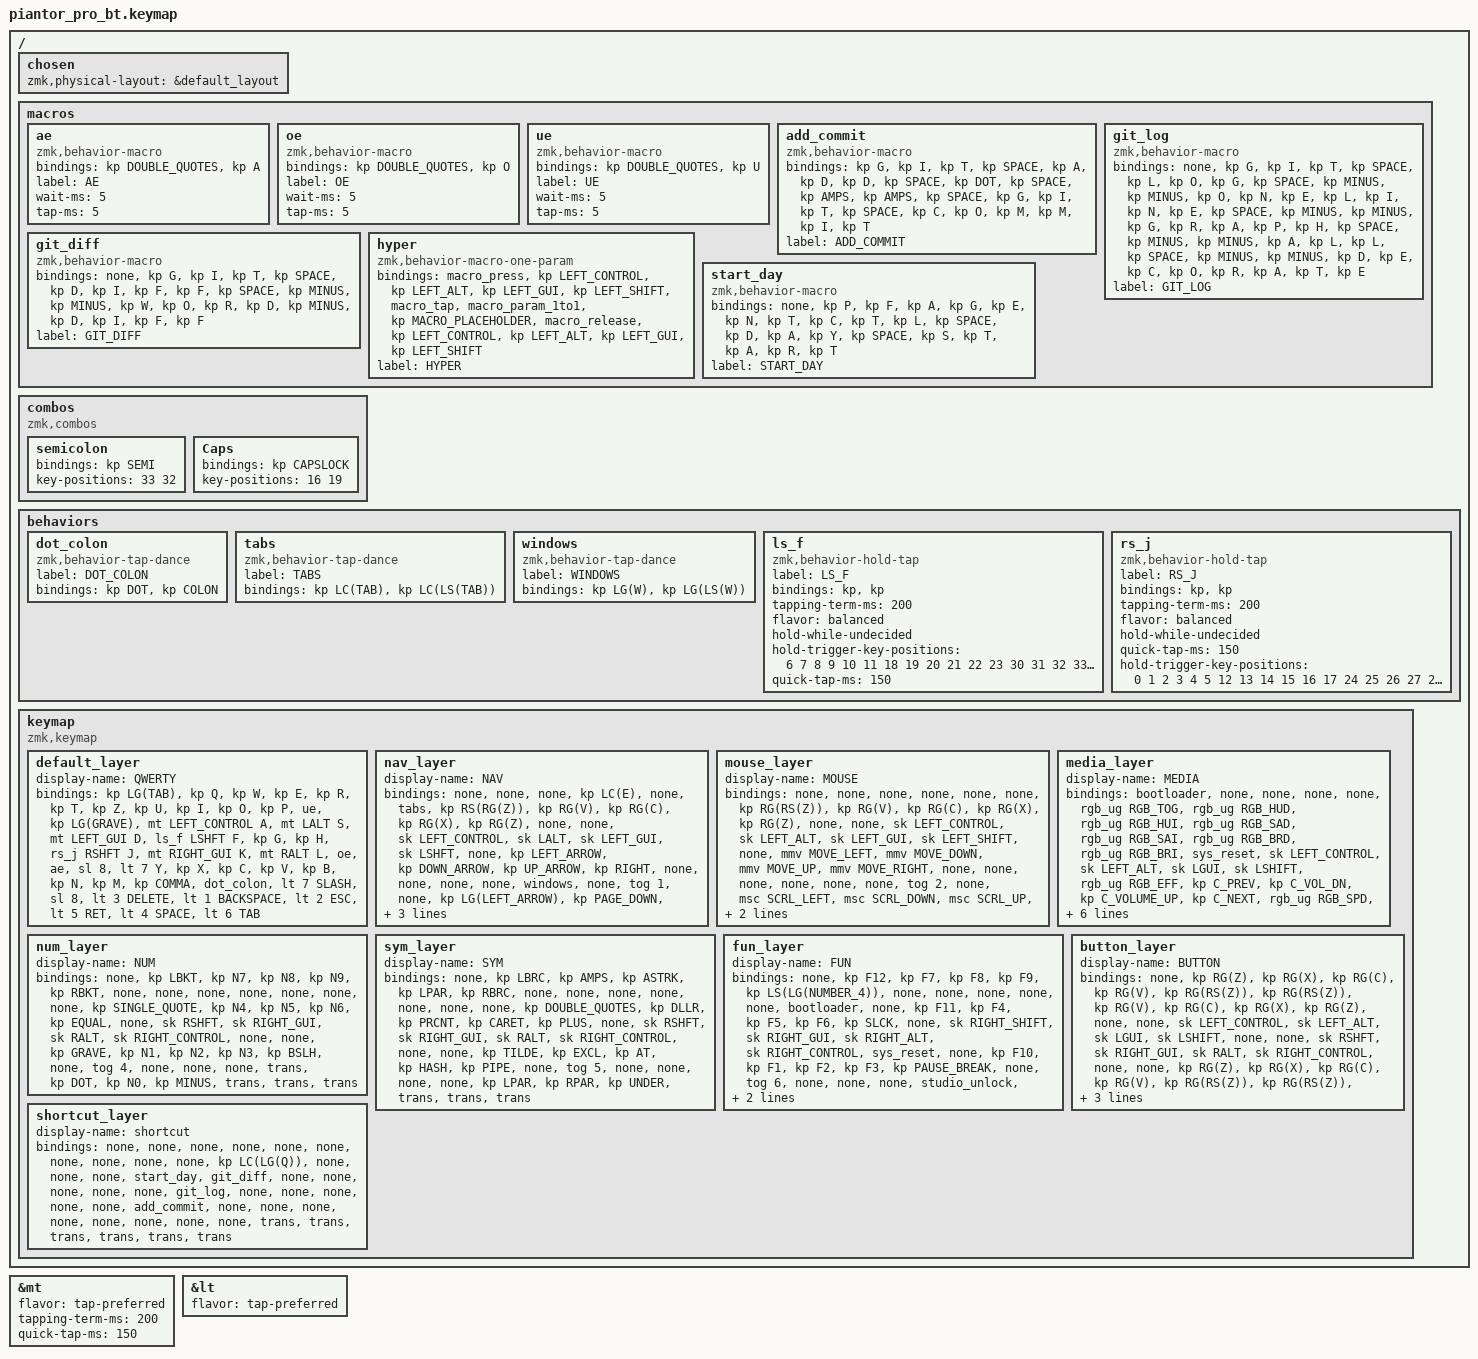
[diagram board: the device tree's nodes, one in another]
/*
 * Copyright (c) 2020 The ZMK Contributors
 *
 * SPDX-License-Identifier: MIT
 */

#define ZMK_POINTING_DEFAULT_MOVE_VAL 2000  // default: 600
#define ZMK_POINTING_DEFAULT_SCRL_VAL 15    // default: 10

#include <behaviors.dtsi>
#include <dt-bindings/zmk/bt.h>
#include <dt-bindings/zmk/keys.h>
#include <dt-bindings/zmk/pointing.h>
#include <dt-bindings/zmk/rgb.h>

&mt {
    flavor = "tap-preferred";
    tapping-term-ms = <200>;
    quick-tap-ms = <150>;
};

&lt { flavor = "tap-preferred"; };

/ {
    chosen { zmk,physical-layout = &default_layout; };

    macros {
        ae: ae {
            compatible = "zmk,behavior-macro";
            #binding-cells = <0>;
            bindings = <&kp DOUBLE_QUOTES &kp A>;
            label = "AE";
            wait-ms = <5>;
            tap-ms = <5>;
        };

        oe: oe {
            compatible = "zmk,behavior-macro";
            #binding-cells = <0>;
            bindings = <&kp DOUBLE_QUOTES &kp O>;
            label = "OE";
            wait-ms = <5>;
            tap-ms = <5>;
        };

        ue: ue {
            compatible = "zmk,behavior-macro";
            #binding-cells = <0>;
            bindings = <&kp DOUBLE_QUOTES &kp U>;
            label = "UE";
            wait-ms = <5>;
            tap-ms = <5>;
        };

        add_commit: add_commit {
            compatible = "zmk,behavior-macro";
            #binding-cells = <0>;
            bindings = <&kp G &kp I &kp T &kp SPACE &kp A &kp D &kp D &kp SPACE &kp DOT &kp SPACE &kp AMPS &kp AMPS &kp SPACE &kp G &kp I &kp T &kp SPACE &kp C &kp O &kp M &kp M &kp I &kp T>;
            label = "ADD_COMMIT";
        };

        git_log: git_log {
            compatible = "zmk,behavior-macro";
            #binding-cells = <0>;
            bindings = <&none &kp G &kp I &kp T &kp SPACE &kp L &kp O &kp G &kp SPACE &kp MINUS &kp MINUS &kp O &kp N &kp E &kp L &kp I &kp N &kp E &kp SPACE &kp MINUS &kp MINUS &kp G &kp R &kp A &kp P &kp H &kp SPACE &kp MINUS &kp MINUS &kp A &kp L &kp L &kp SPACE &kp MINUS &kp MINUS &kp D &kp E &kp C &kp O &kp R &kp A &kp T &kp E>;
            label = "GIT_LOG";
        };

        git_diff: git_diff {
            compatible = "zmk,behavior-macro";
            #binding-cells = <0>;
            bindings = <&none &kp G &kp I &kp T &kp SPACE &kp D &kp I &kp F &kp F &kp SPACE &kp MINUS &kp MINUS &kp W &kp O &kp R &kp D &kp MINUS &kp D &kp I &kp F &kp F>;
            label = "GIT_DIFF";
        };

        hyper: hyper {
            compatible = "zmk,behavior-macro-one-param";
            #binding-cells = <1>;
            bindings =
                <&macro_press>,
                <&kp LEFT_CONTROL &kp LEFT_ALT &kp LEFT_GUI &kp LEFT_SHIFT>,
                <&macro_tap>,
                <&macro_param_1to1 &kp MACRO_PLACEHOLDER>,
                <&macro_release>,
                <&kp LEFT_CONTROL &kp LEFT_ALT &kp LEFT_GUI &kp LEFT_SHIFT>;

            label = "HYPER";
        };

        start_day: start_day {
            compatible = "zmk,behavior-macro";
            #binding-cells = <0>;
            bindings = <&none &kp P &kp F &kp A &kp G &kp E &kp N &kp T &kp C &kp T &kp L &kp SPACE &kp D &kp A &kp Y &kp SPACE &kp S &kp T &kp A &kp R &kp T>;
            label = "START_DAY";
        };
    };

    combos {
        compatible = "zmk,combos";

        semicolon {
            bindings = <&kp SEMI>;
            key-positions = <33 32>;
        };

        Caps {
            bindings = <&kp CAPSLOCK>;
            key-positions = <16 19>;
        };
    };

    behaviors {
        dot_colon: dot_colon {
            compatible = "zmk,behavior-tap-dance";
            label = "DOT_COLON";
            #binding-cells = <0>;
            bindings = <&kp DOT>, <&kp COLON>;
        };

        tabs: tabs {
            compatible = "zmk,behavior-tap-dance";
            label = "TABS";
            #binding-cells = <0>;
            bindings = <&kp LC(TAB)>, <&kp LC(LS(TAB))>;
        };

        windows: windows {
            compatible = "zmk,behavior-tap-dance";
            label = "WINDOWS";
            #binding-cells = <0>;
            bindings = <&kp LG(W)>, <&kp LG(LS(W))>;
        };

        ls_f: ls_f {
            compatible = "zmk,behavior-hold-tap";
            label = "LS_F";
            bindings = <&kp>, <&kp>;

            #binding-cells = <2>;
            tapping-term-ms = <200>;
            flavor = "balanced";
            hold-while-undecided;
            hold-trigger-key-positions = <6 7 8 9 10 11 18 19 20 21 22 23 30 31 32 33 34 35 39 40 41>;
            quick-tap-ms = <150>;
        };

        rs_j: rs_j {
            compatible = "zmk,behavior-hold-tap";
            label = "RS_J";
            bindings = <&kp>, <&kp>;

            #binding-cells = <2>;
            tapping-term-ms = <200>;
            flavor = "balanced";
            hold-while-undecided;
            quick-tap-ms = <150>;
            hold-trigger-key-positions = <0 1 2 3 4 5 12 13 14 15 16 17 24 25 26 27 28 29 36 37 38>;
        };
    };
};

/ {
    keymap {
        compatible = "zmk,keymap";

        default_layer {
            display-name = "QWERTY";

            //---------------------------------------------------------------------------------
            //| LG+TAB | Q | W | E | R | T | Z | U | I | O | P | UE |
            //| LG+` | A/CTRL | S/ALT | D/GUI | F/SHIFT | G | H | J/RSHIFT | K/RGUI | L/RALT | 0/RCTRL | AE |
            //| SL8 | Y/LT7 | X | C | V | B | N | M | '/\" | ./: | /?/! | SL8 |
            //| DEL/LT3 | BSPC/LT1 | ESC/LT2 | RET/LT5 | SPC/LT4 | TAB/LT6 |

            bindings = <
&kp LG(TAB)  &kp Q  &kp W  &kp E  &kp R  &kp T  &kp Z  &kp U  &kp I  &kp O  &kp P  &ue  &kp LG(GRAVE)  &mt LEFT_CONTROL A  &mt LALT S  &mt LEFT_GUI D  &ls_f LSHFT F  &kp G  &kp H  &rs_j RSHFT J  &mt RIGHT_GUI K  &mt RALT L  &oe  &ae  &sl 8  &lt 7 Y  &kp X  &kp C  &kp V  &kp B  &kp N  &kp M  &kp COMMA  &dot_colon  &lt 7 SLASH  &sl 8  &lt 3 DELETE  &lt 1 BACKSPACE  &lt 2 ESC  &lt 5 RET  &lt 4 SPACE  &lt 6 TAB
            >;
        };

        nav_layer {
            display-name = "NAV";

            //-----------------------------------------------------------------------------------
            //|      |     |     | LC+E |     | TABS | REDO | PASTE | COPY | CUT | UNDO |      |
            //|      | CTRL | ALT | GUI | SHIFT |     | LEFT | DOWN | UP | RIGHT |     |      |
            //|      |     |     |     | WINDOWS | TOG MOUSE |     | LG+LEFT | PGDN | RG+PGUP | LG+RIGHT | LG+SPACE |
            //| TRANS | TRANS | TRANS | ENTER | SPACE | TAB |

            bindings = <
&none  &none  &none  &kp LC(E)  &none  &tabs  &kp RS(RG(Z))  &kp RG(V)  &kp RG(C)  &kp RG(X)  &kp RG(Z)  &none  &none  &sk LEFT_CONTROL  &sk LALT  &sk LEFT_GUI  &sk LSHFT  &none  &kp LEFT_ARROW  &kp DOWN_ARROW  &kp UP_ARROW  &kp RIGHT  &none  &none  &none  &none  &windows  &none  &tog 1  &none  &kp LG(LEFT_ARROW)  &kp PAGE_DOWN  &kp PAGE_UP  &kp LG(RIGHT)  &kp LG(SPACE)  &none  &trans  &trans  &trans  &kp ENTER  &kp SPACE  &kp TAB
            >;
        };

        mouse_layer {
            display-name = "MOUSE";

            //-----------------------------------------------------------------------------------
            //|      |     |     |     |     |     | REDO | PASTE | COPY | CUT | UNDO |      |
            //|      | CTRL | ALT | GUI | SHIFT |     | MOVE LEFT | MOVE DOWN | MOVE UP | MOVE RIGHT |     |      |
            //|      |     |     |     |     |     | TOG MOUSE |     | SCROLL LEFT | SCROLL DOWN | SCROLL UP | SCROLL RIGHT |
            //| TRANS | TRANS | TRANS | RCLICK | LCLICK | MCLICK |

            bindings = <
&none  &none  &none  &none  &none  &none  &kp RG(RS(Z))  &kp RG(V)  &kp RG(C)  &kp RG(X)  &kp RG(Z)  &none  &none  &sk LEFT_CONTROL  &sk LEFT_ALT  &sk LEFT_GUI  &sk LEFT_SHIFT  &none  &mmv MOVE_LEFT  &mmv MOVE_DOWN  &mmv MOVE_UP  &mmv MOVE_RIGHT  &none  &none  &none  &none  &none  &none  &tog 2  &none  &msc SCRL_LEFT  &msc SCRL_DOWN  &msc SCRL_UP  &msc SCRL_RIGHT  &none  &none  &trans  &trans  &trans  &mkp RCLK  &mkp LCLK  &mkp MCLK
            >;
        };

        media_layer {
            display-name = "MEDIA";

            //-----------------------------------------------------------------------------
            //| BOOT |     |     |     |     | RGB TOG | HUD | HUI | SAD | SAI | BRD | BRI |
            //| RESET | CTRL | ALT | GUI | SHIFT | EFFECT | PREV | VOL- | VOL+ | NEXT | SPD | SPI |
            //| UNLOCK | RESET | BOOT | UNLOCK | TOG NUM |     | BT CLR | BT1 | BT2 | BT3 | BT4 | BT5 |
            //| TRANS | TRANS | TRANS | STOP | PLAY/PAUSE | MUTE |

            bindings = <
&bootloader  &none  &none  &none  &none  &rgb_ug RGB_TOG  &rgb_ug RGB_HUD  &rgb_ug RGB_HUI  &rgb_ug RGB_SAD  &rgb_ug RGB_SAI  &rgb_ug RGB_BRD  &rgb_ug RGB_BRI  &sys_reset  &sk LEFT_CONTROL  &sk LEFT_ALT  &sk LGUI  &sk LSHIFT  &rgb_ug RGB_EFF  &kp C_PREV  &kp C_VOL_DN  &kp C_VOLUME_UP  &kp C_NEXT  &rgb_ug RGB_SPD  &rgb_ug RGB_SPI  &studio_unlock  &sys_reset  &bootloader  &studio_unlock  &tog 3  &bt BT_CLR  &bt BT_SEL 0  &bt BT_SEL 1  &bt BT_SEL 2  &bt BT_SEL 3  &bt BT_SEL 4  &none  &trans  &trans  &trans  &kp C_STOP  &kp C_PLAY_PAUSE  &kp C_MUTE
            >;
        };

        num_layer {
            display-name = "NUM";

            //----------------------------------------------------------------------------
            //|   | [ | 7 | 8 | 9 | ] |     |     |     |     |     | TRANS |
            //|   | ` | 4 | 5 | 6 | = |     | RSHIFT | RGUI | RALT | RCTRL | TRANS |
            //|   |   | 1 | 2 | 3 | \ |     | TOG SYM |     |     |     | TRANS |
            //| . | 0 | - | TRANS | TRANS | TRANS |

            bindings = <
&none  &kp LBKT  &kp N7  &kp N8  &kp N9  &kp RBKT  &none  &none  &none  &none  &none  &none  &none  &kp SINGLE_QUOTE  &kp N4  &kp N5  &kp N6  &kp EQUAL  &none  &sk RSHFT  &sk RIGHT_GUI  &sk RALT  &sk RIGHT_CONTROL  &none  &none  &kp GRAVE  &kp N1  &kp N2  &kp N3  &kp BSLH  &none  &tog 4  &none  &none  &none  &trans  &kp DOT  &kp N0  &kp MINUS  &trans  &trans  &trans
            >;
        };

        sym_layer {
            display-name = "SYM";

            //-----------------------------------------------------------------------------
            //| TRANS | { | & | * | ( | } |     |     |     |     |     | TRANS |
            //| TRANS | ~ | $ | % | ^ | + |     | RSHIFT | RGUI | RALT | RCTRL | TRANS |
            //| TRANS | NONE | ! | @ | # | | |     | TOG FUN |     |     |     | TRANS |
            //| ( | ) | _ | TRANS | TRANS | TRANS |

            bindings = <
&none  &kp LBRC  &kp AMPS  &kp ASTRK  &kp LPAR  &kp RBRC  &none  &none  &none  &none  &none  &none  &none  &kp DOUBLE_QUOTES  &kp DLLR  &kp PRCNT  &kp CARET  &kp PLUS  &none  &sk RSHFT  &sk RIGHT_GUI  &sk RALT  &sk RIGHT_CONTROL  &none  &none  &kp TILDE  &kp EXCL  &kp AT  &kp HASH  &kp PIPE  &none  &tog 5  &none  &none  &none  &none  &kp LPAR  &kp RPAR  &kp UNDER  &trans  &trans  &trans
            >;
        };

        fun_layer {
            display-name = "FUN";

            //------------------------------------------------------------------------------
            //| TRANS | F12 | F7 | F8 | F9 | SCREENSHOT |     |     |     |     |     | TRANS |
            //| TRANS | F11 | F4 | F5 | F6 | SCROLL LOCK |     | RSHIFT | RGUI | RALT | RCTRL | TRANS |
            //| TRANS | F10 | F1 | F2 | F3 | PAUSE |     | TOG ADJUST |     |     |     | TRANS |
            //| DEL | BSPC | ESC | TRANS | TRANS | TRANS |

            bindings = <
&none  &kp F12  &kp F7  &kp F8  &kp F9  &kp LS(LG(NUMBER_4))  &none  &none  &none  &none  &none  &bootloader  &none  &kp F11  &kp F4  &kp F5  &kp F6  &kp SLCK  &none  &sk RIGHT_SHIFT  &sk RIGHT_GUI  &sk RIGHT_ALT  &sk RIGHT_CONTROL  &sys_reset  &none  &kp F10  &kp F1  &kp F2  &kp F3  &kp PAUSE_BREAK  &none  &tog 6  &none  &none  &none  &studio_unlock  &kp DEL  &kp BACKSPACE  &kp ESC  &trans  &trans  &trans
            >;
        };

        button_layer {
            display-name = "BUTTON";

            //-------------------------------------------------------------------------
            //|      | REDO | CUT | COPY | PASTE | UNDO | UNDO | PASTE | COPY | CUT | REDO |      |
            //|      | CTRL | ALT | GUI | SHIFT |     |     | RSHIFT | RGUI | RALT | RCTRL |      |
            //|      | REDO | CUT | COPY | PASTE | UNDO | UNDO | PASTE | COPY | CUT | REDO |      |
            //| MCLICK | LCLICK | RCLICK | RCLICK | LCLICK | MCLICK |

            bindings = <
&none  &kp RG(Z)  &kp RG(X)  &kp RG(C)  &kp RG(V)  &kp RG(RS(Z))  &kp RG(RS(Z))  &kp RG(V)  &kp RG(C)  &kp RG(X)  &kp RG(Z)  &none  &none  &sk LEFT_CONTROL  &sk LEFT_ALT  &sk LGUI  &sk LSHIFT  &none  &none  &sk RSHFT  &sk RIGHT_GUI  &sk RALT  &sk RIGHT_CONTROL  &none  &none  &kp RG(Z)  &kp RG(X)  &kp RG(C)  &kp RG(V)  &kp RG(RS(Z))  &kp RG(RS(Z))  &kp RG(V)  &kp RG(C)  &kp RG(X)  &kp RG(Z)  &none  &mkp MCLK  &mkp LCLK  &mkp RCLK  &mkp RCLK  &mkp LCLK  &mkp MCLK
            >;
        };

        shortcut_layer {
            display-name = "shortcut";

            //-------------------------------------------------------------------------
            //|                                      SCREENSHOT                          |
            //|                          (Left Shift + Left GUI + 4)                     |

            bindings = <
&none  &none  &none  &none  &none  &none  &none  &none  &none  &none  &kp LC(LG(Q))  &none  &none  &none  &start_day  &git_diff  &none  &none  &none  &none  &none  &git_log  &none  &none  &none  &none  &none  &add_commit  &none  &none  &none  &none  &none  &none  &none  &none  &trans  &trans  &trans  &trans  &trans  &trans
            >;
        };
    };
};
